# CC1314R10 register map
File version: 1.0
CPU: CM33 1.0, other endian, MPU, FPU, 3 interrupt priority bits
Registers are 32-bit, read-write, reset 0x0 unless marked. A register's access mark holds for its fields unless they carry their own. Offsets are from the block's base; [hi:lo] are bit positions; 'fields as' and 'values as' point back to an identical list.

## GPT0 — General Purpose Timer.
Base 0x40010000
0x00 CFG — Configuration
  [2:0] CFG — [2:0] GPT Configuration 0x2- 0x3 - Reserved 0x5- 0x7 - Reserved
    4=16BIT_TIMER (16-bit timer configuration. Configure for two 16-bit timers. Also see TAMR.TAMR and TBMR.TBMR.); 0=32BIT_TIMER (32-bit timer configuration)
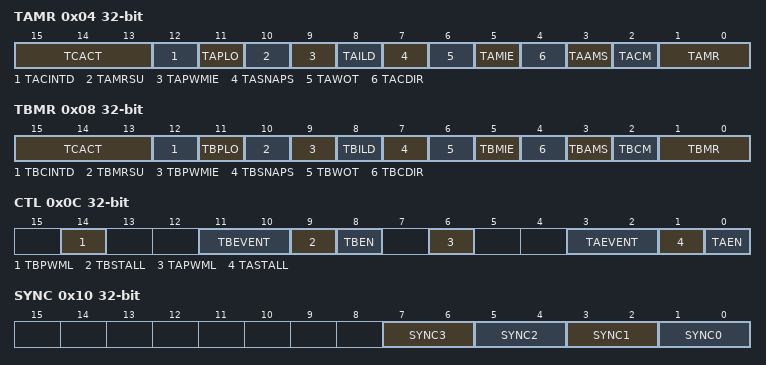
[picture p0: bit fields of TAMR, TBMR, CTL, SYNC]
0x04 TAMR — Timer A Mode
  [15:13] TCACT — [15:13] Timer Compare Action Select
    7=CLRSET_ON_TO (Clear CCP output pin immediately and set on Time-Out); 6=SETCLR_ON_TO (Set CCP output pin immediately and clear on Time-Out); 5=CLRTOG_ON_TO (Clear CCP output pin immediately and toggle on Time-Out); 4=SETTOG_ON_TO (Set CCP output pin immediately and toggle on Time-Out); 3=SET_ON_TO (Set CCP output pin on Time-Out); 2=CLR_ON_TO (Clear CCP output pin on Time-Out); 1=TOG_ON_TO (Toggle State on Time-Out); 0=DIS_CMP (Disable compare operations)
  [12] TACINTD — [12:12] One-Shot/Periodic Interrupt Disable
    1=DIS_TO_INTR (Time-out interrupt are disabled); 0=EN_TO_INTR (Time-out interrupt function as normal)
  [11] TAPLO — [11:11] GPTM Timer A PWM Legacy Operation 0 Legacy operation with CCP pin driven Low when the TAILR register is reloaded after the timer reaches 0. 1 CCP is driven High when the TAILR register is reloaded after the timer reaches 0. This bit is only valid in PWM mode.
    1=CCP_ON_TO (CCP output pin is set to 1 on time-out); 0=LEGACY (Legacy operation)
  [10] TAMRSU — [10:10] Timer A Match Register Update mode This bit defines when the TAMATCHR and TAPR registers are updated. If the timer is disabled (CTL.TAEN = 0) when this bit is set, TAMATCHR and TAPR are updated when the timer is enabled. If the timer is stalled (CTL.TASTALL = 1) when this bit is set, TAMATCHR and TAPR are updated according to the configuration of this bit.
    1=TOUPDATE (Update TAMATCHR and TAPR, if used, on the next time-out.); 0=CYCLEUPDATE (Update TAMATCHR and TAPR, if used, on the next cycle.)
  [9] TAPWMIE — [9:9] GPTM Timer A PWM Interrupt Enable This bit enables interrupts in PWM mode on rising, falling, or both edges of the CCP output, as defined by the CTL.TAEVENT In addition, when this bit is set and a capture event occurs, Timer A automatically generates triggers to the DMA if the trigger capability is enabled by setting the CTL.TAOTE bit and the DMAEV.CAEDMAEN bit respectively. 0 Capture event interrupt is disabled. 1 Capture event interrupt is enabled. This bit is only valid in PWM mode.
    1=EN (Interrupt is enabled. This bit is only valid in PWM mode.); 0=DIS (Interrupt is disabled.)
  [8] TAILD — [8:8] GPT Timer A PWM Interval Load Write
    1=TOUPDATE (Update the TAR register with the value in the TAILR register on the next timeout. If the prescaler is used, update the TAPS register with the value in the TAPR register on the next timeout.); 0=CYCLEUPDATE (Update the TAR register with the value in the TAILR register on the next clock cycle. If the pre-scaler is used, update the TAPS register with the value in the TAPR register on the next clock cycle.)
  [7] TASNAPS — [7:7] GPT Timer A Snap-Shot Mode
    1=EN (If Timer A is configured in the periodic mode, the actual free-running value of Timer A is loaded at the time-out event into the GPT Timer A (TAR) register.); 0=DIS (Snap-shot mode is disabled.)
  [6] TAWOT — [6:6] GPT Timer A Wait-On-Trigger
    1=WAIT (If Timer A is enabled (CTL.TAEN = 1), Timer A does not begin counting until it receives a trigger from the timer in the previous position in the daisy chain. This bit must be clear for GPT Module 0, Timer A. This function is valid for one-shot, periodic, and PWM modes); 0=NOWAIT (Timer A begins counting as soon as it is enabled.)
  [5] TAMIE — [5:5] GPT Timer A Match Interrupt Enable
    1=EN (An interrupt is generated when the match value in TAMATCHR is reached in the one-shot and periodic modes.); 0=DIS (The match interrupt is disabled for match events. Additionally, output triggers on match events are prevented.)
  [4] TACDIR — [4:4] GPT Timer A Count Direction
    1=UP (The timer counts up. When counting up, the timer starts from a value of 0x0.); 0=DOWN (The timer counts down.)
  [3] TAAMS — [3:3] GPT Timer A Alternate Mode Note: To enable PWM mode, you must also clear TACM and then configure TAMR field to 0x2.
    1=PWM (PWM mode is enabled); 0=CAP_COMP (Capture/Compare mode is enabled.)
  [2] TACM — [2:2] GPT Timer A Capture Mode
    1=EDGTIME (Edge-Time mode); 0=EDGCNT (Edge-Count mode)
  [1:0] TAMR — [1:0] GPT Timer A Mode 0x0 Reserved 0x1 One-Shot Timer mode 0x2 Periodic Timer mode 0x3 Capture mode The Timer mode is based on the timer configuration defined by bits 2:0 in the CFG register
    3=CAPTURE (Capture mode); 2=PERIODIC (Periodic Timer mode); 1=ONE_SHOT (One-Shot Timer mode)
0x08 TBMR — Timer B Mode
  [15:13] TCACT — [15:13] Timer Compare Action Select
    values as TAMR.TCACT
  [12] TBCINTD — [12:12] One-Shot/Periodic Interrupt Mode
    1=DIS_TO_INTR (Mask Time-Out Interrupt); 0=EN_TO_INTR (Normal Time-Out Interrupt)
  [11] TBPLO — [11:11] GPTM Timer B PWM Legacy Operation 0 Legacy operation with CCP pin driven Low when the TBILR register is reloaded after the timer reaches 0. 1 CCP is driven High when the TBILR register is reloaded after the timer reaches 0. This bit is only valid in PWM mode.
    values as TAMR.TAPLO
  [10] TBMRSU — [10:10] Timer B Match Register Update mode This bit defines when the TBMATCHR and TBPR registers are updated If the timer is disabled (CTL.TBEN is clear) when this bit is set, TBMATCHR and TBPR are updated when the timer is enabled. If the timer is stalled (CTL.TBSTALL is set) when this bit is set, TBMATCHR and TBPR are updated according to the configuration of this bit.
    1=TOUPDATE (Update TBMATCHR and TBPR, if used, on the next time-out.); 0=CYCLEUPDATE (Update TBMATCHR and TBPR, if used, on the next cycle.)
  [9] TBPWMIE — [9:9] GPTM Timer B PWM Interrupt Enable This bit enables interrupts in PWM mode on rising, falling, or both edges of the CCP output, as defined by the CTL.TBEVENT In addition, when this bit is set and a capture event occurs, Timer A automatically generates triggers to the DMA if the trigger capability is enabled by setting the CTL.TBOTE bit and the DMAEV.CBEDMAEN bit respectively. 0 Capture event interrupt is disabled. 1 Capture event interrupt is enabled. This bit is only valid in PWM mode.
    values as TAMR.TAPWMIE
  [8] TBILD — [8:8] GPT Timer B PWM Interval Load Write
    1=TOUPDATE (Update the TBR register with the value in the TBILR register on the next timeout. If the prescaler is used, update the TBPS register with the value in the TBPR register on the next timeout.); 0=CYCLEUPDATE (Update the TBR register with the value in the TBILR register on the next clock cycle. If the pre-scaler is used, update the TBPS register with the value in the TBPR register on the next clock cycle.)
  [7] TBSNAPS — [7:7] GPT Timer B Snap-Shot Mode
    1=EN (If Timer B is configured in the periodic mode); 0=DIS (Snap-shot mode is disabled.)
  [6] TBWOT — [6:6] GPT Timer B Wait-On-Trigger
    1=WAIT (If Timer B is enabled (CTL.TBEN is set), Timer B does not begin counting until it receives a trigger from the timer in the previous position in the daisy chain. This function is valid for one-shot, periodic, and PWM modes); 0=NOWAIT (Timer B begins counting as soon as it is enabled.)
  [5] TBMIE — [5:5] GPT Timer B Match Interrupt Enable.
    1=EN (An interrupt is generated when the match value in the TBMATCHR register is reached in the one-shot and periodic modes.); 0=DIS (The match interrupt is disabled for match events. Additionally, output triggers on match events are prevented.)
  [4] TBCDIR — [4:4] GPT Timer B Count Direction
    values as TAMR.TACDIR
  [3] TBAMS — [3:3] GPT Timer B Alternate Mode Note: To enable PWM mode, you must also clear TBCM bit and configure TBMR field to 0x2.
    values as TAMR.TAAMS
  [2] TBCM — [2:2] GPT Timer B Capture Mode
    1=EDGTIME (Edge-Time mode); 0=EDGCNT (Edge-Count mode)
  [1:0] TBMR — [1:0] GPT Timer B Mode 0x0 Reserved 0x1 One-Shot Timer mode 0x2 Periodic Timer mode 0x3 Capture mode The Timer mode is based on the timer configuration defined by bits 2:0 in the CFG register
    values as TAMR.TAMR
0x0C CTL — Control
  [14] TBPWML — [14:14] GPT Timer B PWM Output Level 0: Output is unaffected. 1: Output is inverted.
    1=INVERTED; 0=NORMAL (Not inverted)
  [11:10] TBEVENT — [11:10] GPT Timer B Event Mode The values in this register are defined as follows: Value Description 0x0 Positive edge 0x1 Negative edge 0x2 Reserved 0x3 Both edges Note: If PWM output inversion is enabled, edge detection interrupt behavior is reversed. Thus, if a positive-edge interrupt trigger has been set and the PWM inversion generates a postive edge, no event-trigger interrupt asserts. Instead, the interrupt is generated on the negative edge of the PWM signal.
    3=BOTH (Both edges); 1=NEG (Negative edge); 0=POS (Positive edge)
  [9] TBSTALL — [9:9] GPT Timer B Stall Enable
    1=EN (Timer B freezes counting while the processor is halted by the debugger.); 0=DIS (Timer B continues counting while the processor is halted by the debugger.)
  [8] TBEN — [8:8] GPT Timer B Enable
    1=EN (Timer B is enabled and begins counting or the capture logic is enabled based on CFG register.); 0=DIS (Timer B is disabled.)
  [6] TAPWML — [6:6] GPT Timer A PWM Output Level
    1=INVERTED; 0=NORMAL (Not inverted)
  [3:2] TAEVENT — [3:2] GPT Timer A Event Mode The values in this register are defined as follows: Value Description 0x0 Positive edge 0x1 Negative edge 0x2 Reserved 0x3 Both edges Note: If PWM output inversion is enabled, edge detection interrupt behavior is reversed. Thus, if a positive-edge interrupt trigger has been set and the PWM inversion generates a postive edge, no event-trigger interrupt asserts. Instead, the interrupt is generated on the negative edge of the PWM signal.
    values as TBEVENT
  [1] TASTALL — [1:1] GPT Timer A Stall Enable
    1=EN (Timer A freezes counting while the processor is halted by the debugger.); 0=DIS (Timer A continues counting while the processor is halted by the debugger.)
  [0] TAEN — [0:0] GPT Timer A Enable
    1=EN (Timer A is enabled and begins counting or the capture logic is enabled based on the CFG register.); 0=DIS (Timer A is disabled.)
0x10 SYNC — Synch Register
  [7:6] SYNC3 wo — [7:6] Synchronize GPT Timer 3.
    3=BOTH (A timeout event for both Timer A and Timer B of GPT3 is triggered); 2=TIMERB (A timeout event for Timer B of GPT3 is triggered); 1=TIMERA (A timeout event for Timer A of GPT3 is triggered); 0=NOSYNC (No Sync. GPT3 is not affected.)
  [5:4] SYNC2 wo — [5:4] Synchronize GPT Timer 2.
    3=BOTH (A timeout event for both Timer A and Timer B of GPT2 is triggered); 2=TIMERB (A timeout event for Timer B of GPT2 is triggered); 1=TIMERA (A timeout event for Timer A of GPT2 is triggered); 0=NOSYNC (No Sync. GPT2 is not affected.)
  [3:2] SYNC1 wo — [3:2] Synchronize GPT Timer 1
    3=BOTH (A timeout event for both Timer A and Timer B of GPT1 is triggered); 2=TIMERB (A timeout event for Timer B of GPT1 is triggered); 1=TIMERA (A timeout event for Timer A of GPT1 is triggered); 0=NOSYNC (No Sync. GPT1 is not affected.)
  [1:0] SYNC0 wo — [1:0] Synchronize GPT Timer 0
    3=BOTH (A timeout event for both Timer A and Timer B of GPT0 is triggered); 2=TIMERB (A timeout event for Timer B of GPT0 is triggered); 1=TIMERA (A timeout event for Timer A of GPT0 is triggered); 0=NOSYNC (No Sync. GPT0 is not affected.)
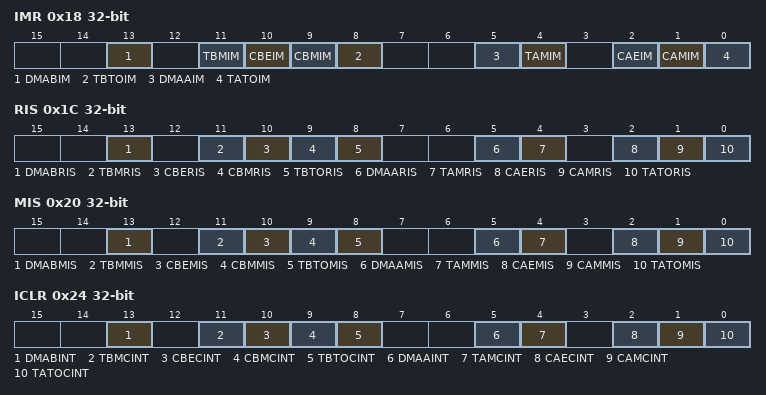
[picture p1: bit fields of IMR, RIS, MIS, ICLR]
0x18 IMR — Interrupt Mask This register is used to enable the interrupts. Associated registers: RIS, MIS, ICLR
  [all] fields
    1=EN (Enable Interrupt); 0=DIS (Disable Interrupt)
  [13] DMABIM — [13:13] Enabling this bit will make the RIS.DMABRIS interrupt propagate to MIS.DMABMIS
  [11] TBMIM — [11:11] Enabling this bit will make the RIS.TBMRIS interrupt propagate to MIS.TBMMIS
  [10] CBEIM — [10:10] Enabling this bit will make the RIS.CBERIS interrupt propagate to MIS.CBEMIS
  [9] CBMIM — [9:9] Enabling this bit will make the RIS.CBMRIS interrupt propagate to MIS.CBMMIS
  [8] TBTOIM — [8:8] Enabling this bit will make the RIS.TBTORIS interrupt propagate to MIS.TBTOMIS
  [5] DMAAIM — [5:5] Enabling this bit will make the RIS.DMAARIS interrupt propagate to MIS.DMAAMIS
  [4] TAMIM — [4:4] Enabling this bit will make the RIS.TAMRIS interrupt propagate to MIS.TAMMIS
  [2] CAEIM — [2:2] Enabling this bit will make the RIS.CAERIS interrupt propagate to MIS.CAEMIS
  [1] CAMIM — [1:1] Enabling this bit will make the RIS.CAMRIS interrupt propagate to MIS.CAMMIS
  [0] TATOIM — [0:0] Enabling this bit will make the RIS.TATORIS interrupt propagate to MIS.TATOMIS
0x1C RIS — Raw Interrupt Status Associated registers: IMR, MIS, ICLR
  [13] DMABRIS ro — [13:13] GPT Timer B DMA Done Raw Interrupt Status 0: Transfer has not completed 1: Transfer has completed
  [11] TBMRIS ro — [11:11] GPT Timer B Match Raw Interrupt 0: The match value has not been reached 1: The match value is reached. TBMR.TBMIE is set, and the match values in TBMATCHR and optionally TBPMR have been reached when configured in one-shot or periodic mode.
  [10] CBERIS ro — [10:10] GPT Timer B Capture Mode Event Raw Interrupt 0: The event has not occured. 1: The event has occured. This interrupt asserts when the subtimer is configured in Input Edge-Time mode
  [9] CBMRIS ro — [9:9] GPT Timer B Capture Mode Match Raw Interrupt 0: The capture mode match for Timer B has not occurred. 1: A capture mode match has occurred for Timer B. This interrupt asserts when the values in the TBR and TBPR match the values in the TBMATCHR and TBPMR when configured in Input Edge-Time mode. This bit is cleared by writing a 1 to the ICLR.CBMCINT bit.
  [8] TBTORIS ro — [8:8] GPT Timer B Time-out Raw Interrupt 0: Timer B has not timed out 1: Timer B has timed out. This interrupt is asserted when a one-shot or periodic mode timer reaches its count limit. The count limit is 0 or the value loaded into TBILR, depending on the count direction.
  [5] DMAARIS ro — [5:5] GPT Timer A DMA Done Raw Interrupt Status 0: Transfer has not completed 1: Transfer has completed
  [4] TAMRIS ro — [4:4] GPT Timer A Match Raw Interrupt 0: The match value has not been reached 1: The match value is reached. TAMR.TAMIE is set, and the match values in TAMATCHR and optionally TAPMR have been reached when configured in one-shot or periodic mode.
  [2] CAERIS ro — [2:2] GPT Timer A Capture Mode Event Raw Interrupt 0: The event has not occured. 1: The event has occured. This interrupt asserts when the subtimer is configured in Input Edge-Time mode
  [1] CAMRIS ro — [1:1] GPT Timer A Capture Mode Match Raw Interrupt 0: The capture mode match for Timer A has not occurred. 1: A capture mode match has occurred for Timer A. This interrupt asserts when the values in the TAR and TAPR match the values in the TAMATCHR and TAPMR when configured in Input Edge-Time mode. This bit is cleared by writing a 1 to the ICLR.CAMCINT bit.
  [0] TATORIS ro — [0:0] GPT Timer A Time-out Raw Interrupt 0: Timer A has not timed out 1: Timer A has timed out. This interrupt is asserted when a one-shot or periodic mode timer reaches its count limit. The count limit is 0 or the value loaded into TAILR, depending on the count direction.
0x20 MIS — Masked Interrupt Status Values are result of bitwise AND operation between RIS and IMR Assosciated clear register: ICLR
  [13] DMABMIS ro — [13:13] 0: No interrupt or interrupt not enabled 1: RIS.DMABRIS = 1 && IMR.DMABIM = 1
  [11] TBMMIS ro — [11:11] 0: No interrupt or interrupt not enabled 1: RIS.TBMRIS = 1 && IMR.TBMIM = 1
  [10] CBEMIS ro — [10:10] 0: No interrupt or interrupt not enabled 1: RIS.CBERIS = 1 && IMR.CBEIM = 1
  [9] CBMMIS ro — [9:9] 0: No interrupt or interrupt not enabled 1: RIS.CBMRIS = 1 && IMR.CBMIM = 1
  [8] TBTOMIS ro — [8:8] 0: No interrupt or interrupt not enabled 1: RIS.TBTORIS = 1 && IMR.TBTOIM = 1
  [5] DMAAMIS ro — [5:5] 0: No interrupt or interrupt not enabled 1: RIS.DMAARIS = 1 && IMR.DMAAIM = 1
  [4] TAMMIS ro — [4:4] 0: No interrupt or interrupt not enabled 1: RIS.TAMRIS = 1 && IMR.TAMIM = 1
  [2] CAEMIS ro — [2:2] 0: No interrupt or interrupt not enabled 1: RIS.CAERIS = 1 && IMR.CAEIM = 1
  [1] CAMMIS ro — [1:1] 0: No interrupt or interrupt not enabled 1: RIS.CAMRIS = 1 && IMR.CAMIM = 1
  [0] TATOMIS ro — [0:0] 0: No interrupt or interrupt not enabled 1: RIS.TATORIS = 1 && IMR.TATOIM = 1
0x24 ICLR — Interrupt Clear This register is used to clear status bits in the RIS and MIS registers
  [13] DMABINT — [13:13] 0: Do nothing. 1: Clear RIS.DMABRIS and MIS.DMABMIS
  [11] TBMCINT — [11:11] 0: Do nothing. 1: Clear RIS.TBMRIS and MIS.TBMMIS
  [10] CBECINT — [10:10] 0: Do nothing. 1: Clear RIS.CBERIS and MIS.CBEMIS
  [9] CBMCINT — [9:9] 0: Do nothing. 1: Clear RIS.CBMRIS and MIS.CBMMIS
  [8] TBTOCINT — [8:8] 0: Do nothing. 1: Clear RIS.TBTORIS and MIS.TBTOMIS
  [5] DMAAINT — [5:5] 0: Do nothing. 1: Clear RIS.DMAARIS and MIS.DMAAMIS
  [4] TAMCINT — [4:4] 0: Do nothing. 1: Clear RIS.TAMRIS and MIS.TAMMIS
  [2] CAECINT — [2:2] 0: Do nothing. 1: Clear RIS.CAERIS and MIS.CAEMIS
  [1] CAMCINT — [1:1] 0: Do nothing. 1: Clear RIS.CAMRIS and MIS.CAMMIS
  [0] TATOCINT — [0:0] 0: Do nothing. 1: Clear RIS.TATORIS and MIS.TATOMIS
0x28 TAILR reset 0xFFFFFFFF — Timer A Interval Load Register
  [31:0] TAILR — [31:0] GPT Timer A Interval Load Register Writing this field loads the counter for Timer A. A read returns the current value of TAILR.
0x2C TBILR reset 0xFFFF — Timer B Interval Load Register
  [31:0] TBILR — [31:0] GPT Timer B Interval Load Register Writing this field loads the counter for Timer B. A read returns the current value of TBILR.
0x30 TAMATCHR reset 0xFFFFFFFF — Timer A Match Register Interrupts can be generated when the timer value is equal to the value in this register in one-shot or periodic mode. In Edge-Count mode, this register along with TAILR, determines how many edge events are counted. The total number of edge events counted is equal to the value in TAILR minus this value. Note that in edge-count mode, when executing an up-count, the value of TAPR and TAILR must be greater than the value of TAPMR and this register. In PWM mode, this value along with TAILR, determines the duty cycle of the output PWM signal. When a 16/32-bit GPT is configured to one of the 32-bit modes, TAMATCHR appears as a 32-bit register. (The upper 16-bits correspond to the contents TBMATCHR). In a 16-bit mode, the upper 16 bits of this register read as 0s and have no effect on the state of TBMATCHR. Note : This register is updated internally (takes effect) based on TAMR.TAMRSU
  [31:0] TAMATCHR — [31:0] GPT Timer A Match Register
0x34 TBMATCHR reset 0xFFFF — Timer B Match Register When a GPT is configured to one of the 32-bit modes, the contents of bits 15:0 in this register are loaded into the upper 16 bits of TAMATCHR. Reads from this register return the current match value of Timer B and writes are ignored. In a 16-bit mode, bits 15:0 are used for the match value. Bits 31:16 are reserved in both cases. Note : This register is updated internally (takes effect) based on TBMR.TBMRSU
  [15:0] TBMATCHR — [15:0] GPT Timer B Match Register
0x38 TAPR — Timer A Pre-scale This register allows software to extend the range of the timers when they are used individually. When in one-shot or periodic down count modes, this register acts as a true prescaler for the timer counter. When acting as a true prescaler, the prescaler counts down to 0 before the value in TAR and TAV registers are incremented. In all other individual/split modes, this register is a linear extension of the upper range of the timer counter, holding bits 23:16 in the 16-bit modes of the 16/32-bit GPT.
  [7:0] TAPSR — [7:0] Timer A Pre-scale. Prescaler ratio in one-shot and periodic count mode is TAPSR + 1, that is: 0: Prescaler ratio = 1 1: Prescaler ratio = 2 2: Prescaler ratio = 3 ... 255: Prescaler ratio = 256
0x3C TBPR — Timer B Pre-scale This register allows software to extend the range of the timers when they are used individually. When in one-shot or periodic down count modes, this register acts as a true prescaler for the timer counter. When acting as a true prescaler, the prescaler counts down to 0 before the value in TBR and TBV registers are incremented. In all other individual/split modes, this register is a linear extension of the upper range of the timer counter, holding bits 23:16 in the 16-bit modes of the 16/32-bit GPT.
  [7:0] TBPSR — [7:0] Timer B Pre-scale. Prescale ratio in one-shot and periodic count mode is TBPSR + 1, that is: 0: Prescaler ratio = 1 1: Prescaler ratio = 2 2: Prescaler ratio = 3 ... 255: Prescaler ratio = 256
0x40 TAPMR — Timer A Pre-scale Match This register allows software to extend the range of the TAMATCHR when used individually.
  [7:0] TAPSMR — [7:0] GPT Timer A Pre-scale Match. In 16 bit mode this field holds bits 23 to 16.
0x44 TBPMR — Timer B Pre-scale Match This register allows software to extend the range of the TBMATCHR when used individually.
  [7:0] TBPSMR — [7:0] GPT Timer B Pre-scale Match Register. In 16 bit mode this field holds bits 23 to 16.
0x48 TAR reset 0xFFFFFFFF — Timer A Register This register shows the current value of the Timer A counter in all cases except for Input Edge Count and Time modes. In the Input Edge Count mode, this register contains the number of edges that have occurred. In the Input Edge Time mode, this register contains the time at which the last edge event took place. When a GPT is configured to one of the 32-bit modes, this register appears as a 32-bit register (the upper 16-bits correspond to the contents of the Timer B (TBR) register). In the16-bit Input Edge Count, Input Edge Time, and PWM modes, bits 15:0 contain the value of the counter and bits 23:16 contain the value of the prescaler, which is the upper 8 bits of the count. Bits 31:24 always read as 0. To read the value of the prescaler in 16-bit One-Shot and Periodic modes, read bits [23:16] in the TAV register. To read the value of the prescalar in periodic snapshot mode, read the Timer A Prescale Snapshot (TAPS) register.
  [31:0] TAR ro — [31:0] GPT Timer A Register Based on the value in the register field TAMR.TAILD, this register is updated with the value from TAILR register either on the next cycle or on the next timeout. A read returns the current value of the Timer A Count Register, in all cases except for Input Edge count and Timer modes. In the Input Edge Count Mode, this register contains the number of edges that have occurred. In the Input Edge Time mode, this register contains the time at which the last edge event took place.
0x4C TBR reset 0xFFFF — Timer B Register This register shows the current value of the Timer B counter in all cases except for Input Edge Count and Time modes. In the Input Edge Count mode, this register contains the number of edges that have occurred. In the Input Edge Time mode, this register contains the time at which the last edge event took place. When a GPTM is configured to one of the 32-bit modes, the contents of bits 15:0 in this register are loaded into the upper 16 bits of the TAR register. Reads from this register return the current value of Timer B. In a 16-bit mode, bits 15:0 contain the value of the counter and bits 23:16 contain the value of the prescaler in Input Edge Count, Input Edge Time, and PWM modes, which is the upper 8 bits of the count. Bits 31:24 always read as 0. To read the value of the prescaler in 16-bit One-Shot and Periodic modes, read bits [23:16] in the TBV register. To read the value of the prescalar in periodic snapshot mode, read the Timer B Prescale Snapshot (TBPS) register.
  [31:0] TBR ro — [31:0] GPT Timer B Register Based on the value in the register field TBMR.TBILD, this register is updated with the value from TBILR register either on the next cycle or on the next timeout. A read returns the current value of the Timer B Count Register, in all cases except for Input Edge count and Timer modes. In the Input Edge Count Mode, this register contains the number of edges that have occurred. In the Input Edge Time mode, this register contains the time at which the last edge event took place.
0x50 TAV reset 0xFFFFFFFF — Timer A Value When read, this register shows the current, free-running value of Timer A in all modes. Softwarecan use this value to determine the time elapsed between an interrupt and the ISR entry when using the snapshot feature with the periodic operating mode. When written, the value written into this register is loaded into the TAR register on the next clock cycle. When a 16/32-bit GPTM is configured to one of the 32-bit modes, this register appears as a 32-bit register (the upper 16-bits correspond to the contents of the GPTM Timer B Value (TBV) register). In a 16-bit mode, bits 15:0 contain the value of the counter and bits 23:16 contain the current, free-running value of the prescaler, which is the upper 8 bits of the count in Input Edge Count, Input Edge Time, PWM and one-shot or periodic up count modes. In one-shot or periodic down count modes, the prescaler stored in 23:16 is a true prescaler, meaning bits 23:16 count down before decrementing the value in bits 15:0. The prescaler in bits 31:24 always reads as 0.
  [31:0] TAV — [31:0] GPT Timer A Register A read returns the current, free-running value of Timer A in all modes. When written, the value written into this register is loaded into the TAR register on the next clock cycle. Note: In 16-bit mode, only the lower 16-bits of this register can be written with a new value. Writes to the prescaler bits have no effect
0x54 TBV reset 0xFFFF — Timer B Value When read, this register shows the current, free-running value of Timer B in all modes. Software can use this value to determine the time elapsed between an interrupt and the ISR entry. When written, the value written into this register is loaded into the TBR register on the next clock cycle. When a 16/32-bit GPTM is configured to one of the 32-bit modes, the contents of bits 15:0 in this register are loaded into the upper 16 bits of the TAV register. Reads from this register return the current free-running value of Timer B. In a 16-bit mode, bits 15:0 contain the value of the counter and bits 23:16 contain the current, free-running value of the prescaler, which is the upper 8 bits of the count in Input Edge Count, Input Edge Time, PWM and one-shot or periodic up count modes. In one-shot or periodic down count modes, the prescaler stored in 23:16 is a true prescaler, meaning bits 23:16 count down before decrementing the value in bits 15:0. The prescaler in bits 31:24 always reads as 0.
  [31:0] TBV — [31:0] GPT Timer B Register A read returns the current, free-running value of Timer B in all modes. When written, the value written into this register is loaded into the TBR register on the next clock cycle. Note: In 16-bit mode, only the lower 16-bits of this register can be written with a new value. Writes to the prescaler bits have no effect
0x5C TAPS — Timer A Pre-scale Snap-shot Based on the value in the register field TAMR.TAILD, this register is updated with the value from TAPR register either on the next cycle or on the next timeout. This register shows the current value of the Timer A pre-scaler in the 16-bit mode.
  [7:0] PSS ro — [7:0] GPT Timer A Pre-scaler
0x60 TBPS — Timer B Pre-scale Snap-shot Based on the value in the register field TBMR.TBILD, this register is updated with the value from TBPR register either on the next cycle or on the next timeout. This register shows the current value of the Timer B pre-scaler in the 16-bit mode.
  [7:0] PSS ro — [7:0] GPT Timer B Pre-scaler
0x64 TAPV — Timer A Pre-scale Value This register shows the current value of the Timer A free running pre-scaler in the 16-bit mode.
  [7:0] PSV ro — [7:0] GPT Timer A Pre-scaler Value
0x68 TBPV — Timer B Pre-scale Value This register shows the current value of the Timer B free running pre-scaler in the 16-bit mode.
  [7:0] PSV ro — [7:0] GPT Timer B Pre-scaler Value
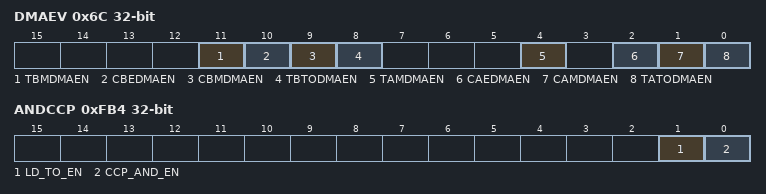
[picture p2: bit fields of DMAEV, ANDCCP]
0x6C DMAEV — DMA Event This register allows software to enable/disable GPT DMA trigger events.
  [11] TBMDMAEN — [11:11] GPT Timer B Match DMA Trigger Enable
  [10] CBEDMAEN — [10:10] GPT Timer B Capture Event DMA Trigger Enable
  [9] CBMDMAEN — [9:9] GPT Timer B Capture Match DMA Trigger Enable
  [8] TBTODMAEN — [8:8] GPT Timer B Time-Out DMA Trigger Enable
  [4] TAMDMAEN — [4:4] GPT Timer A Match DMA Trigger Enable
  [2] CAEDMAEN — [2:2] GPT Timer A Capture Event DMA Trigger Enable
  [1] CAMDMAEN — [1:1] GPT Timer A Capture Match DMA Trigger Enable
  [0] TATODMAEN — [0:0] GPT Timer A Time-Out DMA Trigger Enable
0xFB0 VERSION reset 0x400 — Peripheral Version This register provides information regarding the GPT version
  [31:0] VERSION ro — [31:0] Timer Revision.
0xFB4 ANDCCP — Combined CCP Output This register is used to logically AND CCP output pairs for each timer
  [1] LD_TO_EN — [1:1] PWM assertion would happen at timeout 0: PWM assertion happens when counter matches load value 1: PWM assertion happens at timeout of the counter
  [0] CCP_AND_EN — [0:0] Enables AND operation of the CCP outputs for timers A and B. 0 : PWM outputs of Timer A and Timer B are the internal generated PWM signals of the respective timers. 1 : PWM output of Timer A is ANDed version of Timer A and Timer B PWM signals and Timer B PWM ouput is Timer B PWM signal only.

## GPT1 — General Purpose Timer.
Base 0x40011000
Registers as GPT0; these are added or differ:
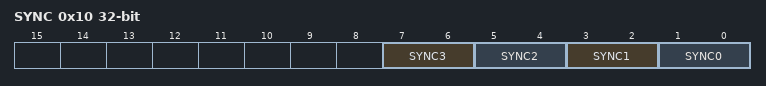
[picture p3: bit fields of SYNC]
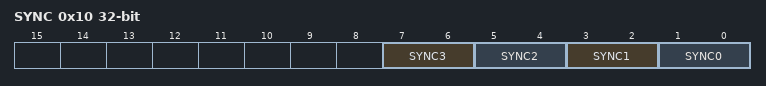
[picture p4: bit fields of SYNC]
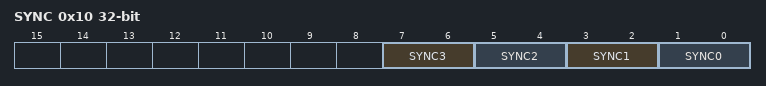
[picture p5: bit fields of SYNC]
0x10 SYNC — Synch Register
  fields as GPT0.SYNC

## GPT2 — General Purpose Timer.
Base 0x40012000
Registers as GPT0; these are added or differ:
0x10 SYNC — Synch Register
  fields as GPT0.SYNC

## GPT3 — General Purpose Timer.
Base 0x40013000
Registers as GPT0; these are added or differ:
0x10 SYNC — Synch Register
  fields as GPT0.SYNC
